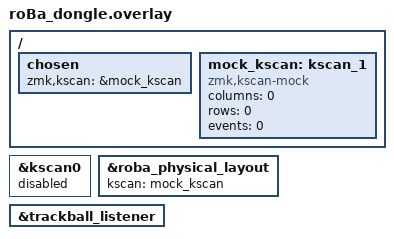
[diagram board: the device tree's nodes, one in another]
#include "roBa.dtsi"

&kscan0 {
	status = "disabled";
};

/ {
   chosen {
      zmk,kscan = &mock_kscan;
   };

   mock_kscan: kscan_1 {
      compatible = "zmk,kscan-mock";
      columns = <0>;
      rows = <0>;
      events = <0>;
   };
};

&roba_physical_layout {
    kscan = <&mock_kscan>;
};

&trackball_listener {
    status = "okay";
};
